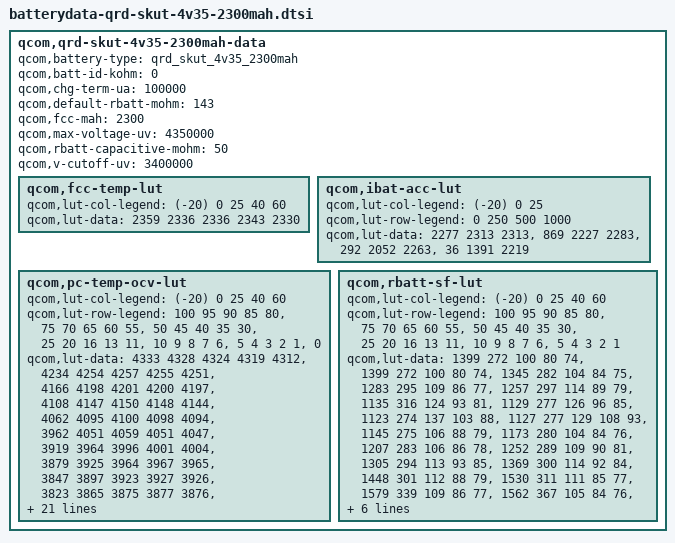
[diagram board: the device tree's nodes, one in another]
/* Copyright (c) 2015, The Linux Foundation. All rights reserved.
 *
 * This program is free software; you can redistribute it and/or modify
 * it under the terms of the GNU General Public License version 2 and
 * only version 2 as published by the Free Software Foundation.
 *
 * This program is distributed in the hope that it will be useful,
 * but WITHOUT ANY WARRANTY; without even the implied warranty of
 * MERCHANTABILITY or FITNESS FOR A PARTICULAR PURPOSE.  See the
 * GNU General Public License for more details.
 */

qcom,qrd-skut-4v35-2300mah-data {
	qcom,battery-type = "qrd_skut_4v35_2300mah";
	qcom,batt-id-kohm = <0>;
	qcom,chg-term-ua = <100000>;
	qcom,default-rbatt-mohm = <143>;
	qcom,fcc-mah = <2300>;
	qcom,max-voltage-uv = <4350000>;
	qcom,rbatt-capacitive-mohm = <50>;
	qcom,v-cutoff-uv = <3400000>;

	qcom,fcc-temp-lut {
		qcom,lut-col-legend = <(-20) 0 25 40 60>;
		qcom,lut-data = <2359 2336 2336 2343 2330>;
	};

	qcom,ibat-acc-lut {
		qcom,lut-col-legend = <(-20) 0 25>;
		qcom,lut-row-legend = <0 250 500 1000>;
		qcom,lut-data = <2277 2313 2313>,
				<869 2227 2283>,
				<292 2052 2263>,
				<36 1391 2219>;
	};

	qcom,pc-temp-ocv-lut {
		qcom,lut-col-legend = <(-20) 0 25 40 60>;
		qcom,lut-row-legend = <100 95 90 85 80>,
					<75 70 65 60 55>,
					<50 45 40 35 30>,
					<25 20 16 13 11>,
					<10 9 8 7 6>,
					<5 4 3 2 1>,
					<0>;
		qcom,lut-data = <4333 4328 4324 4319 4312>,
				<4234 4254 4257 4255 4251>,
				<4166 4198 4201 4200 4197>,
				<4108 4147 4150 4148 4144>,
				<4062 4095 4100 4098 4094>,
				<3962 4051 4059 4051 4047>,
				<3919 3964 3996 4001 4004>,
				<3879 3925 3964 3967 3965>,
				<3847 3897 3923 3927 3926>,
				<3823 3865 3875 3877 3876>,
				<3803 3839 3845 3846 3845>,
				<3785 3814 3822 3823 3822>,
				<3768 3793 3803 3804 3803>,
				<3753 3776 3787 3788 3787>,
				<3738 3759 3773 3771 3767>,
				<3722 3741 3758 3752 3740>,
				<3702 3724 3739 3731 3717>,
				<3681 3715 3715 3708 3693>,
				<3660 3709 3696 3687 3674>,
				<3640 3703 3691 3682 3670>,
				<3627 3698 3690 3681 3669>,
				<3612 3693 3688 3680 3668>,
				<3596 3685 3687 3679 3667>,
				<3575 3674 3684 3676 3664>,
				<3551 3656 3677 3668 3653>,
				<3521 3630 3655 3645 3620>,
				<3483 3594 3615 3601 3573>,
				<3434 3544 3557 3541 3510>,
				<3352 3475 3477 3458 3424>,
				<3253 3366 3354 3329 3293>,
				<3000 3000 3000 3000 3000>;
	};

	qcom,rbatt-sf-lut {
		qcom,lut-col-legend = <(-20) 0 25 40 60>;
		qcom,lut-row-legend = <100 95 90 85 80>,
					<75 70 65 60 55>,
					<50 45 40 35 30>,
					<25 20 16 13 11>,
					<10 9 8 7 6>,
					<5 4 3 2 1>;
		qcom,lut-data = <1399 272 100 80 74>,
				<1399 272 100 80 74>,
				<1345 282 104 84 75>,
				<1283 295 109 86 77>,
				<1257 297 114 89 79>,
				<1135 316 124 93 81>,
				<1129 277 126 96 85>,
				<1123 274 137 103 88>,
				<1127 277 129 108 93>,
				<1145 275 106 88 79>,
				<1173 280 104 84 76>,
				<1207 283 106 86 78>,
				<1252 289 109 90 81>,
				<1305 294 113 93 85>,
				<1369 300 114 92 84>,
				<1448 301 112 88 79>,
				<1530 311 111 85 77>,
				<1579 339 109 86 77>,
				<1562 367 105 84 76>,
				<1429 354 106 84 77>,
				<1467 361 108 86 78>,
				<1497 369 111 89 80>,
				<1536 377 115 91 84>,
				<1567 384 119 94 88>,
				<1619 389 123 96 87>,
				<1762 395 122 94 80>,
				<2077 405 119 90 82>,
				<2770 422 120 93 84>,
				<5539 454 127 98 90>,
				<11078 553 150 123 114>;
	};
};
